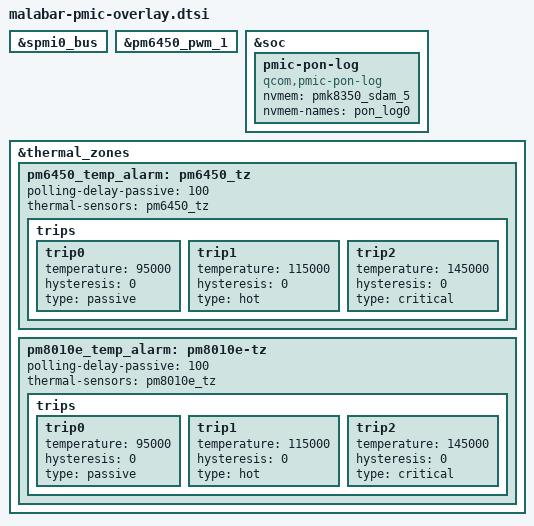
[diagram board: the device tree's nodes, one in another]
// SPDX-License-Identifier: BSD-3-Clause
/*
 * Copyright (c) Qualcomm Technologies, Inc. and/or its subsidiaries.
 */

#include <dt-bindings/gpio/gpio.h>

#include "pmk8350.dtsi"

&spmi0_bus {
	#include "pm6450.dtsi"
	#include "pm8010.dtsi"
};

&pm6450_pwm_1 {
	status = "ok";
};

&soc {
	pmic-pon-log {
		compatible = "qcom,pmic-pon-log";
		nvmem = <&pmk8350_sdam_5>;
		nvmem-names = "pon_log0";
	};
};

&thermal_zones {
	pm6450_temp_alarm: pm6450_tz {
		polling-delay-passive = <100>;
		thermal-sensors = <&pm6450_tz>;

		trips {
			trip0 {
				temperature = <95000>;
				hysteresis = <0>;
				type = "passive";
			};

			trip1 {
				temperature = <115000>;
				hysteresis = <0>;
				type = "hot";
			};

			trip2 {
				temperature = <145000>;
				hysteresis = <0>;
				type = "critical";
			};
		};
	};

	pm8010e_temp_alarm: pm8010e-tz {
		polling-delay-passive = <100>;
		thermal-sensors = <&pm8010e_tz>;

		trips {
			trip0 {
				temperature = <95000>;
				hysteresis = <0>;
				type = "passive";
			};

			trip1 {
				temperature = <115000>;
				hysteresis = <0>;
				type = "hot";
			};

			trip2 {
				temperature = <145000>;
				hysteresis = <0>;
				type = "critical";
			};
		};
	};
};
